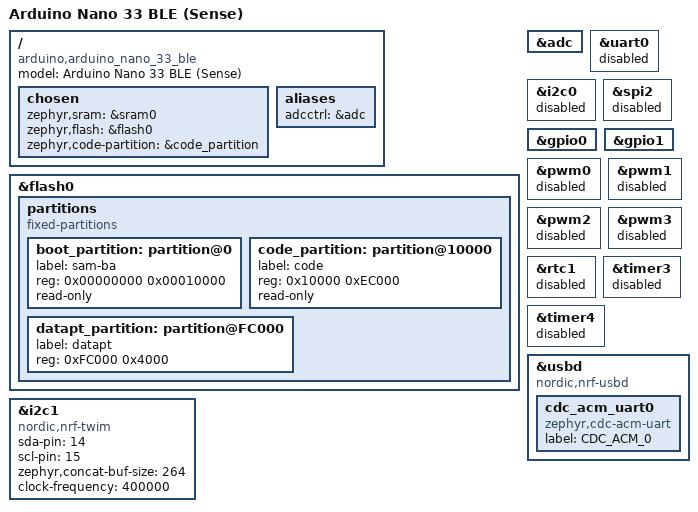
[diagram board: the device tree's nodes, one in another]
/*
 * Copyright (c) 2020 Jefferson Lee
 *
 * SPDX-License-Identifier: Apache-2.0
 */
/dts-v1/;
#include <nordic/nrf52840_qiaa.dtsi>

/ {
	model = "Arduino Nano 33 BLE (Sense)";
	compatible = "arduino,arduino_nano_33_ble";

	chosen {
		zephyr,sram = &sram0;
		zephyr,flash = &flash0;
		zephyr,code-partition = &code_partition;
	};

	aliases {
		adcctrl = &adc;
	};
};

&flash0 {
	partitions {
		compatible = "fixed-partitions";
		#address-cells = <1>;
		#size-cells = <1>;

		boot_partition: partition@0 {
			label = "sam-ba";
			reg = <0x00000000 0x00010000>;
			read-only;
		};

		code_partition: partition@10000 {
			label = "code";
			reg = <0x10000 0xEC000>;
			read-only;
		};

    datapt_partition: partition@FC000 {
        label = "datapt";
        reg = <0xFC000 0x4000>;
    };
	};
};

&adc {
	status = "okay";
};
&uart0 {
  status = "disabled";
};
&i2c0 {
  status = "disabled";
};
&i2c1 {
	compatible = "nordic,nrf-twim";
	status = "okay";
	sda-pin = <14>; //P0.14
	scl-pin = <15>; //P0.15
  zephyr,concat-buf-size = <264>;
  clock-frequency = <400000>;
};
// we use SPI2 because SPI1/0 shares conflicts with I2C1/0
&spi2 {
  status = "disabled";
};

&gpio0 {
	status = "okay";
};

&gpio1 {
	status = "okay";
};

&pwm0 {
	status = "disabled";
};
&pwm1 {
	status = "disabled";
};
&pwm2 {
	status = "disabled";
};
&pwm3 {
	status = "disabled";
};
&rtc1 {
	status = "disabled";
};
&timer3 {
    status = "disabled";
};
&timer4 {
    status = "disabled";
};

zephyr_udc0: &usbd {
	compatible = "nordic,nrf-usbd";
	status = "okay";
  cdc_acm_uart0 {
		compatible = "zephyr,cdc-acm-uart";
		label = "CDC_ACM_0";
	};
};

